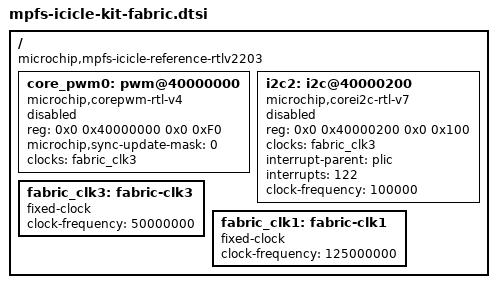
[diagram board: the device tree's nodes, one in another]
// SPDX-License-Identifier: (GPL-2.0 OR MIT)
/* Copyright (c) 2020-2021 Microchip Technology Inc */

/ {
	compatible = "microchip,mpfs-icicle-reference-rtlv2203", "microchip,mpfs";

	core_pwm0: pwm@40000000 {
		compatible = "microchip,corepwm-rtl-v4";
		reg = <0x0 0x40000000 0x0 0xF0>;
		microchip,sync-update-mask = /bits/ 32 <0>;
		#pwm-cells = <2>;
		clocks = <&fabric_clk3>;
		status = "disabled";
	};

	i2c2: i2c@40000200 {
		compatible = "microchip,corei2c-rtl-v7";
		reg = <0x0 0x40000200 0x0 0x100>;
		#address-cells = <1>;
		#size-cells = <0>;
		clocks = <&fabric_clk3>;
		interrupt-parent = <&plic>;
		interrupts = <122>;
		clock-frequency = <100000>;
		status = "disabled";
	};

	fabric_clk3: fabric-clk3 {
		compatible = "fixed-clock";
		#clock-cells = <0>;
		clock-frequency = <50000000>;
	};

	fabric_clk1: fabric-clk1 {
		compatible = "fixed-clock";
		#clock-cells = <0>;
		clock-frequency = <125000000>;
	};
};
